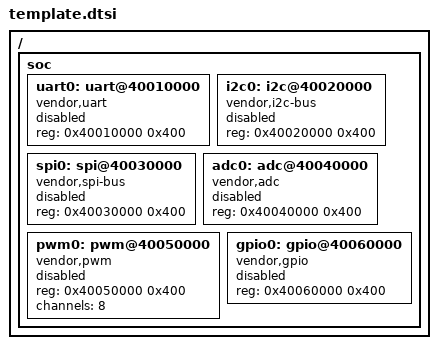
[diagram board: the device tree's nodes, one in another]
/*
 * template.dtsi — SoC 级外设模板
 *
 * 这是 mini_tree 的 SoC 设备树模板，按 Linux DTS 规范编写：
 *   - 所有外设默认 status = "disabled"
 *   - 板级 board.dts 通过 #include 导入，用 &label 覆写使能
 *
 * 移植到新平台时:
 *   1. 复制此文件为 soc/<your-soc>.dtsi
 *   2. 替换 compatible / reg 为实际值
 *   3. 在 board.dts 中 #include 并 &label 使能所需外设
 */
#ifndef _SOC_TEMPLATE_DTSI
#define _SOC_TEMPLATE_DTSI

/ {
    soc {
        #address-cells = <1>;
        #size-cells = <1>;

        uart0: uart@40010000 {
            compatible = "vendor,uart";
            reg = <0x40010000 0x400>;
            status = "disabled";
        };

        i2c0: i2c@40020000 {
            compatible = "vendor,i2c-bus";
            reg = <0x40020000 0x400>;
            status = "disabled";
        };

        spi0: spi@40030000 {
            compatible = "vendor,spi-bus";
            reg = <0x40030000 0x400>;
            status = "disabled";
        };

        adc0: adc@40040000 {
            compatible = "vendor,adc";
            reg = <0x40040000 0x400>;
            status = "disabled";
        };

        pwm0: pwm@40050000 {
            compatible = "vendor,pwm";
            reg = <0x40050000 0x400>;
            channels = <8>;
            status = "disabled";
        };

        gpio0: gpio@40060000 {
            compatible = "vendor,gpio";
            reg = <0x40060000 0x400>;
            status = "disabled";
        };
    };
};

#endif /* _SOC_TEMPLATE_DTSI */
